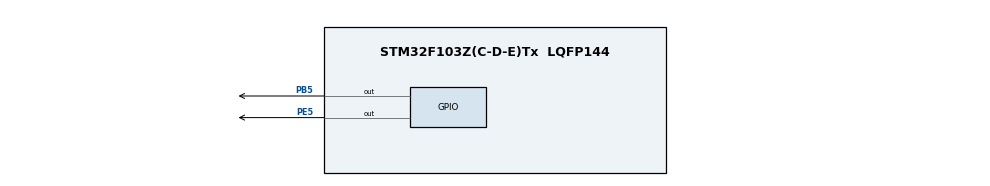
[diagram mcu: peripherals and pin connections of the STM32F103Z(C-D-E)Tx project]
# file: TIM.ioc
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Mcu.Family=STM32F1
Mcu.Name=STM32F103Z(C-D-E)Tx
Mcu.Package=LQFP144
NVIC.PriorityGroup=NVIC_PRIORITYGROUP_4
NVIC.TIM2_IRQn=true\:15\:0\:true\:false\:true\:true\:true
OSC_IN.Mode=HSE-External-Oscillator
OSC_IN.Signal=RCC_OSC_IN
OSC_OUT.Mode=HSE-External-Oscillator
OSC_OUT.Signal=RCC_OSC_OUT
PA13.Mode=JTAG_4_pins
PA13.Signal=SYS_JTMS-SWDIO
PA14.Mode=JTAG_4_pins
PA14.Signal=SYS_JTCK-SWCLK
PA15.Mode=JTAG_4_pins
PA15.Signal=SYS_JTDI
PB3.Mode=JTAG_4_pins
PB3.Signal=SYS_JTDO-TRACESWO
PB5.PinState=GPIO_PIN_SET
PB5.Signal=GPIO_Output
PC14-OSC32_IN.Mode=LSE-External-Oscillator
PC14-OSC32_IN.Signal=RCC_OSC32_IN
PC15-OSC32_OUT.Mode=LSE-External-Oscillator
PC15-OSC32_OUT.Signal=RCC_OSC32_OUT
PE5.Signal=GPIO_Output
ProjectManager.HeapSize=0x200
ProjectManager.StackSize=0x400
ProjectManager.TargetToolchain=EWARM V8.32
RCC.APB1Freq_Value=8000000
RCC.APB2Freq_Value=8000000
RCC.USBFreq_Value=8000000
TIM2.Period=5000-1
TIM2.Prescaler=800-1
VP_TIM2_VS_ClockSourceINT.Mode=Internal
board=custom

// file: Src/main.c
/* USER CODE BEGIN Header */
/**
  ******************************************************************************
  * @file           : main.c
  * @brief          : Main program body
  ******************************************************************************
  * @attention
  *
  * <h2><center>&copy; Copyright (c) 2020 STMicroelectronics.
  * All rights reserved.</center></h2>
  *
  * This software component is licensed by ST under BSD 3-Clause license,
  * the "License"; You may not use this file except in compliance with the
  * License. You may obtain a copy of the License at:
  *                        opensource.org/licenses/BSD-3-Clause
  *
  ******************************************************************************
  */
/* USER CODE END Header */

#include "main.h"

/* USER CODE BEGIN Includes */
#include <stdio.h>
/* USER CODE END Includes */

TIM_HandleTypeDef htim2;

void SystemClock_Config(void);
static void MX_GPIO_Init(void);
static void MX_TIM2_Init(void);

/* USER CODE BEGIN 0 */
void HAL_TIM_PeriodElapsedCallback(TIM_HandleTypeDef *htim){
  HAL_GPIO_TogglePin(GPIOE,GPIO_PIN_5);
  HAL_GPIO_TogglePin(GPIOB,GPIO_PIN_5);
}
/* USER CODE END 0 */

int main(void)
{

  /* MCU Configuration--------------------------------------------------------*/

  /* Reset of all peripherals, Initializes the Flash interface and the Systick. */
  HAL_Init();

  /* Configure the system clock */
  SystemClock_Config();

  /* Initialize all configured peripherals */
  MX_GPIO_Init();
  MX_TIM2_Init();
  /* USER CODE BEGIN 2 */
  HAL_TIM_Base_Start_IT(&htim2);
  /* USER CODE END 2 */

  /* Infinite loop */
  while (1)
  {

  }
}

void SystemClock_Config(void)
{
  RCC_OscInitTypeDef RCC_OscInitStruct = {0};
  RCC_ClkInitTypeDef RCC_ClkInitStruct = {0};

  /** Initializes the CPU, AHB and APB busses clocks
  */
  RCC_OscInitStruct.OscillatorType = RCC_OSCILLATORTYPE_HSI;
  RCC_OscInitStruct.HSIState = RCC_HSI_ON;
  RCC_OscInitStruct.HSICalibrationValue = RCC_HSICALIBRATION_DEFAULT;
  RCC_OscInitStruct.PLL.PLLState = RCC_PLL_NONE;
  if (HAL_RCC_OscConfig(&RCC_OscInitStruct) != HAL_OK)
  {
    Error_Handler();
  }
  /** Initializes the CPU, AHB and APB busses clocks
  */
  RCC_ClkInitStruct.ClockType = RCC_CLOCKTYPE_HCLK|RCC_CLOCKTYPE_SYSCLK
                              |RCC_CLOCKTYPE_PCLK1|RCC_CLOCKTYPE_PCLK2;
  RCC_ClkInitStruct.SYSCLKSource = RCC_SYSCLKSOURCE_HSI;
  RCC_ClkInitStruct.AHBCLKDivider = RCC_SYSCLK_DIV1;
  RCC_ClkInitStruct.APB1CLKDivider = RCC_HCLK_DIV1;
  RCC_ClkInitStruct.APB2CLKDivider = RCC_HCLK_DIV1;

  if (HAL_RCC_ClockConfig(&RCC_ClkInitStruct, FLASH_LATENCY_0) != HAL_OK)
  {
    Error_Handler();
  }
}

static void MX_TIM2_Init(void)
{

  TIM_ClockConfigTypeDef sClockSourceConfig = {0};
  TIM_MasterConfigTypeDef sMasterConfig = {0};

  htim2.Instance = TIM2;
  htim2.Init.Prescaler = 800-1;
  htim2.Init.CounterMode = TIM_COUNTERMODE_UP;
  htim2.Init.Period = 5000-1;
  htim2.Init.ClockDivision = TIM_CLOCKDIVISION_DIV1;
  htim2.Init.AutoReloadPreload = TIM_AUTORELOAD_PRELOAD_DISABLE;
  if (HAL_TIM_Base_Init(&htim2) != HAL_OK)
  {
    Error_Handler();
  }
  sClockSourceConfig.ClockSource = TIM_CLOCKSOURCE_INTERNAL;
  if (HAL_TIM_ConfigClockSource(&htim2, &sClockSourceConfig) != HAL_OK)
  {
    Error_Handler();
  }
  sMasterConfig.MasterOutputTrigger = TIM_TRGO_RESET;
  sMasterConfig.MasterSlaveMode = TIM_MASTERSLAVEMODE_DISABLE;
  if (HAL_TIMEx_MasterConfigSynchronization(&htim2, &sMasterConfig) != HAL_OK)
  {
    Error_Handler();
  }

}

static void MX_GPIO_Init(void)
{
  GPIO_InitTypeDef GPIO_InitStruct = {0};

  /* GPIO Ports Clock Enable */
  __HAL_RCC_GPIOE_CLK_ENABLE();
  __HAL_RCC_GPIOC_CLK_ENABLE();
  __HAL_RCC_GPIOA_CLK_ENABLE();
  __HAL_RCC_GPIOB_CLK_ENABLE();

  /*Configure GPIO pin Output Level */
  HAL_GPIO_WritePin(GPIOE, GPIO_PIN_5, GPIO_PIN_RESET);

  /*Configure GPIO pin Output Level */
  HAL_GPIO_WritePin(GPIOB, GPIO_PIN_5, GPIO_PIN_SET);

  /*Configure GPIO pin : PE5 */
  GPIO_InitStruct.Pin = GPIO_PIN_5;
  GPIO_InitStruct.Mode = GPIO_MODE_OUTPUT_PP;
  GPIO_InitStruct.Pull = GPIO_NOPULL;
  GPIO_InitStruct.Speed = GPIO_SPEED_FREQ_LOW;
  HAL_GPIO_Init(GPIOE, &GPIO_InitStruct);

  /*Configure GPIO pin : PB5 */
  GPIO_InitStruct.Pin = GPIO_PIN_5;
  GPIO_InitStruct.Mode = GPIO_MODE_OUTPUT_PP;
  GPIO_InitStruct.Pull = GPIO_NOPULL;
  GPIO_InitStruct.Speed = GPIO_SPEED_FREQ_LOW;
  HAL_GPIO_Init(GPIOB, &GPIO_InitStruct);

}

void Error_Handler(void)
{
}

/************************ (C) COPYRIGHT STMicroelectronics *****END OF FILE****/
